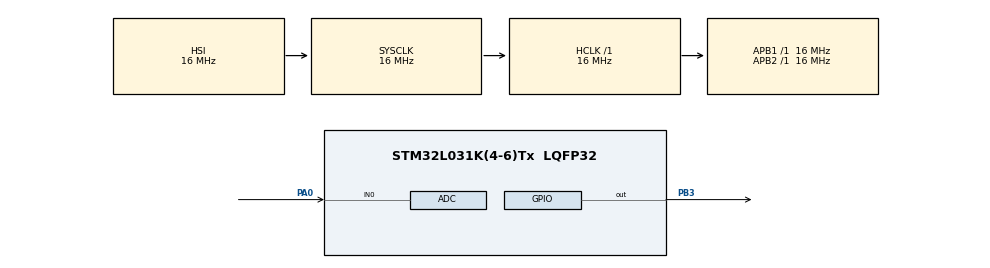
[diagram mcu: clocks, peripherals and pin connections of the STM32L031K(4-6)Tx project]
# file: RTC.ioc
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ADC.SamplingTime=ADC_SAMPLETIME_160CYCLES_5
Mcu.Family=STM32L0
Mcu.Name=STM32L031K(4-6)Tx
Mcu.Package=LQFP32
NVIC.RCC_IRQn=true\:0\:0\:false\:false\:true\:true\:false\:true
PA0-CK_IN.Mode=IN0
PA0-CK_IN.Signal=ADC_IN0
PA13.Mode=Serial_Wire
PA13.Signal=SYS_SWDIO
PA14.Mode=Serial_Wire
PA14.Signal=SYS_SWCLK
PB3.Signal=GPIO_Output
PC14-OSC32_IN.Mode=LSE-External-Oscillator
PC14-OSC32_IN.Signal=RCC_OSC32_IN
PC15-OSC32_OUT.Mode=LSE-External-Oscillator
PC15-OSC32_OUT.Signal=RCC_OSC32_OUT
ProjectManager.HeapSize=0x200
ProjectManager.StackSize=0x400
ProjectManager.TargetToolchain=STM32CubeIDE
RCC.AHBFreq_Value=16000000
RCC.APB1Freq_Value=16000000
RCC.APB1TimFreq_Value=16000000
RCC.APB2Freq_Value=16000000
RCC.APB2TimFreq_Value=16000000
RCC.HCLKFreq_Value=16000000
RCC.HSE_VALUE=8000000
RCC.HSI16_VALUE=16000000
RCC.HSI48_VALUE=48000000
RCC.HSI_VALUE=16000000
RCC.MSI_VALUE=2097000
RCC.PLLMUL=RCC_PLLMUL_4
RCC.RTCClockSelection=RCC_RTCCLKSOURCE_LSE
RCC.SYSCLKFreq_VALUE=16000000
RCC.SYSCLKSource=RCC_SYSCLKSOURCE_HSI
RCC.VCOOutputFreq_Value=64000000
VP_RTC_VS_RTC_Activate.Mode=RTC_Enabled
board=NUCLEO-L031K6

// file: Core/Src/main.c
/* USER CODE BEGIN Header */
/**
  ******************************************************************************
  * @file           : main.c
  * @brief          : Main program body
  ******************************************************************************
  * @attention
  *
  * Copyright (c) 2026 STMicroelectronics.
  * All rights reserved.
  *
  * This software is licensed under terms that can be found in the LICENSE file
  * in the root directory of this software component.
  * If no LICENSE file comes with this software, it is provided AS-IS.
  *
  ******************************************************************************
  */
/* USER CODE END Header */
#include "main.h"

ADC_HandleTypeDef hadc;

RTC_HandleTypeDef hrtc;

/* USER CODE BEGIN PV */
uint32_t val;
float voltage;

volatile uint8_t rtcWakeup = 0;
/* USER CODE END PV */

void SystemClock_Config(void);
static void MX_GPIO_Init(void);
static void MX_RTC_Init(void);
static void MX_ADC_Init(void);

/* USER CODE BEGIN 0 */
void battLevelMonitor(void)
{
	HAL_ADC_Start(&hadc);

	HAL_ADC_PollForConversion(&hadc, 100);

	val = HAL_ADC_GetValue(&hadc);

	voltage = ((val*3.3f)/4095.0f)*2;

	HAL_ADC_Stop(&hadc);
}

void HAL_RTCEx_WakeUpTimerEventCallback(RTC_HandleTypeDef *hrtc)
{
	rtcWakeup = 1;

}
/* USER CODE END 0 */

int main(void)
{

  /* MCU Configuration--------------------------------------------------------*/

  /* Reset of all peripherals, Initializes the Flash interface and the Systick. */
  HAL_Init();

  /* Configure the system clock */

  SystemClock_Config();
  /* Initialize all configured peripherals */
  MX_GPIO_Init();
  MX_RTC_Init();
  MX_ADC_Init();
  /* USER CODE BEGIN 2 */

  HAL_RTCEx_SetWakeUpTimer_IT(&hrtc, 2048, RTC_WAKEUPCLOCK_RTCCLK_DIV16);
  /* USER CODE END 2 */

  /* Infinite loop */
  while (1)
  {

    /* USER CODE BEGIN 3 */
		if(rtcWakeup == 1)
		{
			rtcWakeup = 0;
			battLevelMonitor();
		}

		HAL_Delay(2000);

		// Prevent Systick from waking the CPU every 1 ms
		HAL_SuspendTick();

		HAL_PWR_EnterSTOPMode(PWR_LOWPOWERREGULATOR_ON, PWR_STOPENTRY_WFI);

		SystemClock_Config();

		HAL_ResumeTick();
  }
  /* USER CODE END 3 */
}

void SystemClock_Config(void)
{
  RCC_OscInitTypeDef RCC_OscInitStruct = {0};
  RCC_ClkInitTypeDef RCC_ClkInitStruct = {0};
  RCC_PeriphCLKInitTypeDef PeriphClkInit = {0};

  /** Configure the main internal regulator output voltage
  */
  __HAL_PWR_VOLTAGESCALING_CONFIG(PWR_REGULATOR_VOLTAGE_SCALE1);

  /** Configure LSE Drive Capability
  */
  HAL_PWR_EnableBkUpAccess();
  __HAL_RCC_LSEDRIVE_CONFIG(RCC_LSEDRIVE_LOW);

  /** Initializes the RCC Oscillators according to the specified parameters
  * in the RCC_OscInitTypeDef structure.
  */
  RCC_OscInitStruct.OscillatorType = RCC_OSCILLATORTYPE_HSI|RCC_OSCILLATORTYPE_LSE;
  RCC_OscInitStruct.LSEState = RCC_LSE_ON;
  RCC_OscInitStruct.HSIState = RCC_HSI_ON;
  RCC_OscInitStruct.HSICalibrationValue = RCC_HSICALIBRATION_DEFAULT;
  RCC_OscInitStruct.PLL.PLLState = RCC_PLL_NONE;
  if (HAL_RCC_OscConfig(&RCC_OscInitStruct) != HAL_OK)
  {
    Error_Handler();
  }

  /** Initializes the CPU, AHB and APB buses clocks
  */
  RCC_ClkInitStruct.ClockType = RCC_CLOCKTYPE_HCLK|RCC_CLOCKTYPE_SYSCLK
                              |RCC_CLOCKTYPE_PCLK1|RCC_CLOCKTYPE_PCLK2;
  RCC_ClkInitStruct.SYSCLKSource = RCC_SYSCLKSOURCE_HSI;
  RCC_ClkInitStruct.AHBCLKDivider = RCC_SYSCLK_DIV1;
  RCC_ClkInitStruct.APB1CLKDivider = RCC_HCLK_DIV1;
  RCC_ClkInitStruct.APB2CLKDivider = RCC_HCLK_DIV1;

  if (HAL_RCC_ClockConfig(&RCC_ClkInitStruct, FLASH_LATENCY_0) != HAL_OK)
  {
    Error_Handler();
  }
  PeriphClkInit.PeriphClockSelection = RCC_PERIPHCLK_RTC;
  PeriphClkInit.RTCClockSelection = RCC_RTCCLKSOURCE_LSE;
  if (HAL_RCCEx_PeriphCLKConfig(&PeriphClkInit) != HAL_OK)
  {
    Error_Handler();
  }
}

static void MX_ADC_Init(void)
{

  ADC_ChannelConfTypeDef sConfig = {0};

  /** Configure the global features of the ADC (Clock, Resolution, Data Alignment and number of conversion)
  */
  hadc.Instance = ADC1;
  hadc.Init.OversamplingMode = DISABLE;
  hadc.Init.ClockPrescaler = ADC_CLOCK_SYNC_PCLK_DIV1;
  hadc.Init.Resolution = ADC_RESOLUTION_12B;
  hadc.Init.SamplingTime = ADC_SAMPLETIME_160CYCLES_5;
  hadc.Init.ScanConvMode = ADC_SCAN_DIRECTION_FORWARD;
  hadc.Init.DataAlign = ADC_DATAALIGN_RIGHT;
  hadc.Init.ContinuousConvMode = DISABLE;
  hadc.Init.DiscontinuousConvMode = DISABLE;
  hadc.Init.ExternalTrigConvEdge = ADC_EXTERNALTRIGCONVEDGE_NONE;
  hadc.Init.ExternalTrigConv = ADC_SOFTWARE_START;
  hadc.Init.DMAContinuousRequests = DISABLE;
  hadc.Init.EOCSelection = ADC_EOC_SINGLE_CONV;
  hadc.Init.Overrun = ADC_OVR_DATA_PRESERVED;
  hadc.Init.LowPowerAutoWait = DISABLE;
  hadc.Init.LowPowerFrequencyMode = DISABLE;
  hadc.Init.LowPowerAutoPowerOff = DISABLE;
  if (HAL_ADC_Init(&hadc) != HAL_OK)
  {
    Error_Handler();
  }

  /** Configure for the selected ADC regular channel to be converted.
  */
  sConfig.Channel = ADC_CHANNEL_0;
  sConfig.Rank = ADC_RANK_CHANNEL_NUMBER;
  if (HAL_ADC_ConfigChannel(&hadc, &sConfig) != HAL_OK)
  {
    Error_Handler();
  }

}

static void MX_RTC_Init(void)
{

  /** Initialize RTC Only
  */
  hrtc.Instance = RTC;
  hrtc.Init.HourFormat = RTC_HOURFORMAT_24;
  hrtc.Init.AsynchPrediv = 127;
  hrtc.Init.SynchPrediv = 255;
  hrtc.Init.OutPut = RTC_OUTPUT_DISABLE;
  hrtc.Init.OutPutRemap = RTC_OUTPUT_REMAP_NONE;
  hrtc.Init.OutPutPolarity = RTC_OUTPUT_POLARITY_HIGH;
  hrtc.Init.OutPutType = RTC_OUTPUT_TYPE_OPENDRAIN;
  if (HAL_RTC_Init(&hrtc) != HAL_OK)
  {
    Error_Handler();
  }

}

static void MX_GPIO_Init(void)
{
  GPIO_InitTypeDef GPIO_InitStruct = {0};

  /* GPIO Ports Clock Enable */
  __HAL_RCC_GPIOC_CLK_ENABLE();
  __HAL_RCC_GPIOA_CLK_ENABLE();
  __HAL_RCC_GPIOB_CLK_ENABLE();

  /*Configure GPIO pin Output Level */
  HAL_GPIO_WritePin(GPIOB, GPIO_PIN_3, GPIO_PIN_RESET);

  /*Configure GPIO pin : PB3 */
  GPIO_InitStruct.Pin = GPIO_PIN_3;
  GPIO_InitStruct.Mode = GPIO_MODE_OUTPUT_PP;
  GPIO_InitStruct.Pull = GPIO_NOPULL;
  GPIO_InitStruct.Speed = GPIO_SPEED_FREQ_LOW;
  HAL_GPIO_Init(GPIOB, &GPIO_InitStruct);

}

void Error_Handler(void)
{
  __disable_irq();
  while (1)
  {
  }
}
